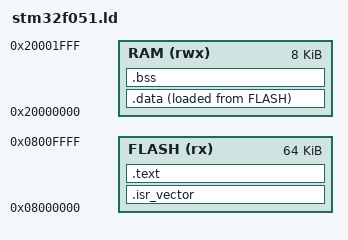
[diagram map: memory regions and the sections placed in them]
/* Linker script for STM32F051R8 */

MEMORY
{
    FLASH (rx)  : ORIGIN = 0x08000000, LENGTH = 64K
    RAM   (rwx) : ORIGIN = 0x20000000, LENGTH = 8K
}

SECTIONS
{
    .isr_vector :
    {
        . = ALIGN(4);
        KEEP(*(.isr_vector))
        . = ALIGN(4);
    } >FLASH

    .text :
    {
        . = ALIGN(4);
        _stext = .;
        *(.text)
        . = ALIGN(4);
        _etext = .;
    } >FLASH

    /* initialized data */
    _sidata = .;
    .data :
    {
        . = ALIGN(4);
        _sdata = .;
        *(.data)
        *(.data*)
        . = ALIGN(4);
        _edata = .;
    } >RAM AT>FLASH

    /* uninitialized data */
    .bss :
    {
        . = ALIGN(4);
        _sbss = .;
        *(.bss)
        *(.bss*)
        *(COMMON)
        . = ALIGN(4);
        _ebss = .;
    } >RAM
}
